# M55M1 register map
File version: 1.0
Registers are 32-bit, read-write, reset 0x0 unless marked. A register's access mark holds for its fields unless they carry their own. Offsets are from the block's base; [hi:lo] are bit positions; {n}, {i} and the like mark numbered series; 'fields as' and 'values as' point back to an identical list.

## I2C0 — I2C Register Map
Base 0x40248000
Same registers: I2C2 0x40249000, I2C1 0x40288000, I2C3 0x40289000, I2C0_NS 0x50248000, I2C2_NS 0x50249000, I2C1_NS 0x50288000, I2C3_NS 0x50289000
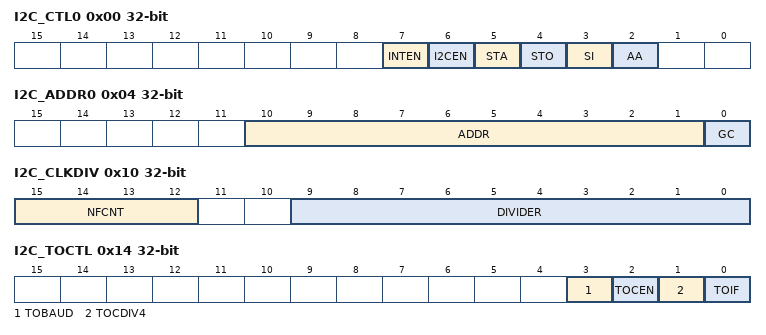
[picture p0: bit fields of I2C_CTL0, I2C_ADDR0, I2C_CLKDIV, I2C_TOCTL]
0x00 I2C_CTL0 — I2C Control Register 0
  [7] INTEN — Enable Interrupt
    0=I2C interrupt Disabled; 1=I2C interrupt Enabled
  [6] I2CEN — I2C Controller Enable Bit
    0=I2C controller Disabled; 1=I2C controller Enabled
  [5] STA — I2C START Control. Setting STA to logic 1 to enter Master mode, the I2C hardware sends a START or repeat START condition to bus when the bus is free. This bit will be cleared by hardware automatically.
  [4] STO — I2C STOP Control. In Master mode, setting STO to transmit a STOP condition to bus then I2C controller will check the bus condition if a STOP condition is detected. This bit will be cleared by hardware automatically.
  [3] SI — I2C Interrupt Flag. When a new I2C state is present in the I2C_STATUS0 register, the SI flag is set by hardware. If bit INTEN (I2C_CTL0 [7]) is set, the I2C interrupt is requested. SI must be cleared by software. Clear SI by writing 1 to this bit. For ACKMEN is set in slave read mode, the SI flag is set in 8th clock period for user to confirm the acknowledge bit and 9th clock period for user to read the data in the data buffer.
  [2] AA — Assert Acknowledge Control
0x04 I2C_ADDR0 — I2C Slave Address Register0
  [10:1] ADDR — I2C Address. The content of this register is irrelevant when I2C is in Master mode. In the slave mode, the seven most significant bits must be loaded with the chip's own address. The I2C hardware will react if either of the address is matched. Note: When software set 10'h000, the address cannot be used.
  [0] GC — General Call Function
    0=General Call Function Disabled; 1=General Call Function Enabled
0x08 I2C_DAT — I2C Data Register
  [7:0] DAT — I2C Data. Bit [7:0] is located with the 8-bit transferred/received data of I2C serial port.
0x0C I2C_STATUS0 ro reset 0xF8 — I2C Status Register 0
  [7:0] STATUS — I2C Status
0x10 I2C_CLKDIV — I2C Clock Divided Register
  [15:12] NFCNT — Noise Filter Count. The register bits control the input filter width. If the pulse width is narrower than the setting((3+N)*PCLK), it will be ignored. 0 : filter width 3*PCLK. 1 : filter width 4*PCLK. N : filter width (3+N)*PCKL. Note: Filter width Min :3*PCLK, Max : 18*PCLK
  [9:0] DIVIDER — I2C Clock Divided. Note: The minimum value of DIVIDER is 4.
0x14 I2C_TOCTL — I2C Time-out Control Register
  [3] TOBAUD — Time-out Counter Input Clock Using Baud Rate Frequency. When enabled, the time-out counter is using baud rate.
    0=Time-out counter is using PCLK or PCLK/4; 1=Time-out counter is using IC baud rate
  [2] TOCEN — Time-out Counter Enable Bit. When enabled, the 14-bit time-out counter will start counting when SI is cleared. Setting flag SI to '1' will reset counter and re-start up counting after SI is cleared.
    0=Time-out counter Disabled; 1=Time-out counter Enabled
  [1] TOCDIV4 — Time-out Counter Input Clock Divided by 4. When enabled, the time-out period is extended 4 times. Note: This bit only worked when I2C_TOCTL[3] is set to 0.
    0=Time-out period is extend 4 times Disabled; 1=Time-out period is extend 4 times Enabled
  [0] TOIF — Time-out Flag. This bit is set by hardware when I2C time-out happened and it can interrupt CPU if I2C interrupt enable bit (INTEN) is set to 1. Note: Software can write 1 to clear this bit.
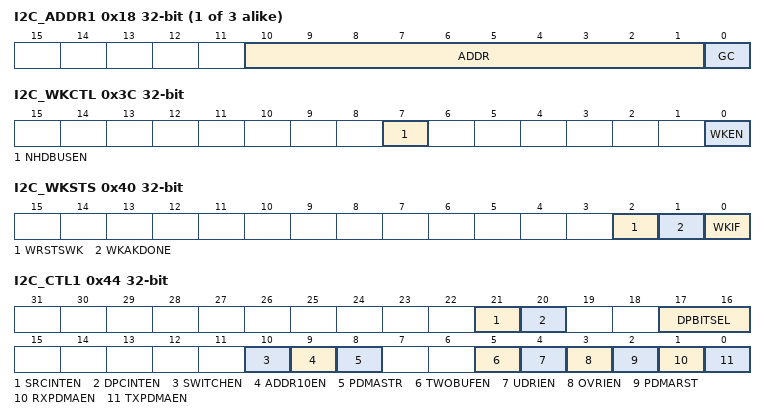
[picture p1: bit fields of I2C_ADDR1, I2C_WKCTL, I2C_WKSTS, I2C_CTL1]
{0x14+4i} I2C_ADDR{i} (i=1..3) — I2C Slave Address Register{i}
  fields as I2C_ADDR0
{0x24+4i} I2C_ADDRMSK{i} (i=0..3) — I2C Slave Address Mask Register{i}
  [10:1] ADDRMSK — I2C Address Mask. I2C bus controllers support multiple address recognition with four address mask register. When the bit in the address mask register is set to one, it means the received corresponding address bit is don't-care. If the bit is set to zero, that means the received corresponding register bit should be exact the same as address register. Note: The wake-up function cannot use address mask in 10-bit mode.
    0=Mask Disabled (the received corresponding register bit should be exact the same as address register.); 1=Mask Enabled (the received corresponding address bit is don't care.)
0x3C I2C_WKCTL — I2C Wake-up Control Register
  [7] NHDBUSEN — I2C No Hold BUS Enable Bit. Note: The I2C controller could respond when WKIF event is not clear, it may cause error data transmitted or received. If data transmitted or received when WKIF event is not clear, user must reset I2C controller and execute the original operation again.
    0=I2C hold bus after wake-up; 1=I2C don't hold bus after wake-up
  [0] WKEN — I2C Wake-up Enable Bit
    0=I2C wake-up function Disabled; 1=I2C wake-up function Enabled
0x40 I2C_WKSTS — I2C Wake-up Status Register
  [2] WRSTSWK — Read/Write Status Bit in Address Wakeup Frame. Note: This bit will be cleared when software can write 1 to WKAKDONE bit.
    0=Write command be record on the address match wakeup frame; 1=Read command be record on the address match wakeup frame
  [1] WKAKDONE — Wakeup Address Frame Acknowledge Bit Done. Note: This bit can't release WKIF. Software can write 1 to clear this bit.
    0=The ACK bit cycle of address match frame isn't done; 1=The ACK bit cycle of address match frame is done in power-down
  [0] WKIF — I2C Wake-up Flag. When chip is woken up from Power-down mode by I2C, this bit is set to 1. Software can write 1 to clear this bit.
0x44 I2C_CTL1 — I2C Control Register 1
  [21] SRCINTEN — Slave Read Command Interrupt Enable Bit
    0=Slave Read Command Interrupt Disabled; 1=Slave Read Command Interrupt Enabled
  [20] DPCINTEN — Data Phase Count Interrupt Enable Bit
    0=Data Phase Count Interrupt Disabled; 1=Data Phase Count Interrupt Enabled
  [17:16] DPBITSEL — Data Phase Bit Count Select
    0=DPCIF never set by hardware; 1=When I2C is transfer data and bit count equal to 6, DPCIF will be set by hardware; 2=When I2C is transfer data and bit count equal to 7, DPCIF will be set by hardware; 3=When I2C is transfer data and bit count equal to 8, DPCIF will be set by hardware
  [10] SWITCHEN — SCL And SDA Pin Switch Enable Bit. Note: Original pin configuration table is shown in Basic Configuration chapter.
    0=IC use original pin configuration; 1=IC switch SCL and SDA pin configuration
  [9] ADDR10EN — Address 10-bit Function Enable Bit
    0=Address match 10-bit function Disabled; 1=Address match 10-bit function Enabled
  [8] PDMASTR — PDMA Stretch Bit
    0=I2C send STOP automatically after PDMA transfer done. (only master TX); 1=I2C SCL bus is stretched by hardware after PDMA transfer done if the SI is not cleared. (only master TX)
  [5] TWOBUFEN — Two-level BUFFER Enable Bit. Set to enable the two-level buffer for I2C transmitted or received buffer. It is used to improve the performance of the I2C bus.
    0=Two-level buffer Disabled; 1=Two-level buffer Enabled
  [4] UDRIEN — I2C Under Run Interrupt Control Bit. Setting UDRIEN to logic 1 will send a interrupt to system when the TWOBUFEN bit is enabled and there is under run event happened in transmitted buffer.
  [3] OVRIEN — I2C over Run Interrupt Control Bit. Setting OVRIEN to logic 1 will send a interrupt to system when the TWOBUFEN bit is enabled and there is over run event in received buffer.
  [2] PDMARST — PDMA Reset
    0=No effect; 1=Reset the I2C request to PDMA
  [1] RXPDMAEN — PDMA Receive Channel Available
    0=Receive PDMA function Disabled; 1=Receive PDMA function Enabled
  [0] TXPDMAEN — PDMA Transmit Channel Available
    0=Transmit PDMA function Disabled; 1=Transmit PDMA function Enabled
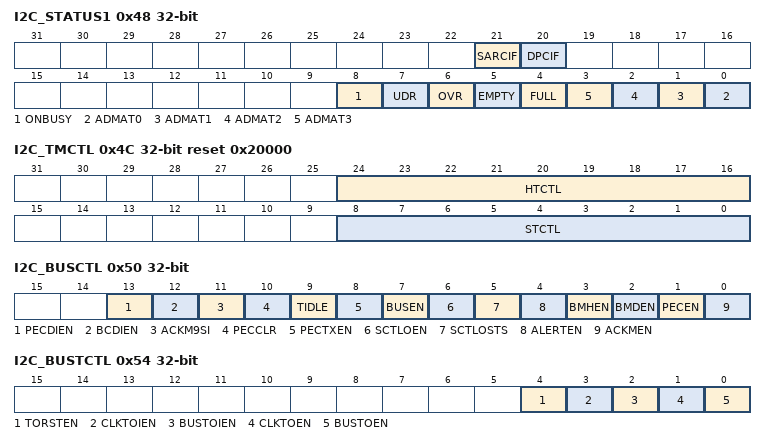
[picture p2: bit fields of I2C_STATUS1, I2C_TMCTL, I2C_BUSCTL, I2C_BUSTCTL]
0x48 I2C_STATUS1 — I2C Status Register 1
  [21] SARCIF — Slave Address Read Command Interrupt Flag. This bit is set by hardware when I2C receive address match read command. This bit is cleared by write 1 to it.
  [20] DPCIF — Data Phase Count Interrupt Flag. This bit is set by hardware when I2C transfer bit count equal to DPBITSEL setting. This bit is cleared by write 1 to it.
  [8] ONBUSY ro — On Bus Busy (Read Only). Indicates that a communication is in progress on the bus. It is set by hardware when a START condition is detected. It is cleared by hardware when a STOP condition is detected.
    0=The bus is IDLE (both SCL and SDA High); 1=The bus is busy
  [7] UDR — I2C Under Run Status Bit. Note: This bit is read only.
  [6] OVR — I2C over Run Status Bit. Note: This bit is read only.
  [5] EMPTY — TWO-LEVEL BUFFER EMPTY. This bit is set when POINTER is equal to 0. Note: This bit is read only.
  [4] FULL — TWO-LEVEL BUFFER FULL. This bit is set when POINTER is equal to 2. Note: This bit is read only.
  [n] ADMAT{n} (n=0..3) — I2C Address {n} Match Status. When address {n} is matched, hardware will inform which address used. This bit will set to 1, and software can write 1 to clear this bit.
0x4C I2C_TMCTL reset 0x20000 — I2C Timing Configure Control Register
  [24:16] HTCTL — Hold Time Configure Control. This field is used to generate the delay timing between SCL falling edge and SDA rising edge in transmission mode.
  [8:0] STCTL — Setup Time Configure Control. This field is used to generate a delay timing between SDA falling edge and SCL rising edge in transmission mode. Note: Setup time setting should not make SCL output less than three PCLKs.
0x50 I2C_BUSCTL — I2C Bus Management Control Register
  [13] PECDIEN — Packet Error Checking Byte Transfer Done Interrupt Enable Bit
    0=PEC transfer done interrupt Disabled; 1=PEC transfer done interrupt Enabled
  [12] BCDIEN — Packet Error Checking Byte Count Done Interrupt Enable Bit
    0=Byte count done interrupt Disabled; 1=Byte count done interrupt Enabled
  [11] ACKM9SI — Acknowledge Manual Enable Extra SI Interrupt
    0=There is no SI interrupt in the 9th clock cycle when the BUSEN =1 and ACKMEN =1; 1=There is SI interrupt in the 9th clock cycle when the BUSEN =1 and ACKMEN =1
  [10] PECCLR — PEC Clear at Repeat Start. The calculation of PEC starts when PECEN is set to 1 and it is cleared when the STA or STO bit is detected. This PECCLR bit is used to enable the condition of REPEAT START can clear the PEC calculation.
    0=PEC calculation is cleared by 'Repeat Start' function Disabled; 1=PEC calculation is cleared by 'Repeat Start' function Enabled
  [9] TIDLE — Timer Check in Idle State. The BUSTOUT is used to calculate the time-out of clock low in bus active and the idle period in bus Idle. This bit is used to define which condition is enabled. Note: The BUSY (I2C_BUSSTS[0]) indicate the current bus state.
    0=BUSTOUT is used to calculate the clock low period in bus active; 1=BUSTOUT is used to calculate the IDLE period in bus Idle
  [8] PECTXEN — Packet Error Checking Byte Transmission/Reception
    0=No PEC transfer; 1=PEC transmission is requested
  [7] BUSEN — BUS Enable Bit. Note: When the bit is enabled, the internal 14-bit counter is used to calculate the time out event of clock low condition.
    0=The system management function Disabled; 1=The system management function Enabled
  [6] SCTLOEN — Suspend or Control Pin Output Enable Bit
    0=The SUSCON pin in input; 1=The output enable is active on the SUSCON pin
  [5] SCTLOSTS — Suspend/Control Data Output Status
    0=The output of SUSCON pin is low; 1=The output of SUSCON pin is high
  [4] ALERTEN — Bus Management Alert Enable Bit
    0=Release the BM_ALERT pin high and Alert Response Header disabled: 0001100x followed by NACK if both of BMDEN and ACKMEN are enabled. BM_ALERT pin not supported; 1=Drive BM_ALERT pin low and Alert Response Address Header enables: 0001100x followed by ACK if both of BMDEN and ACKMEN are enabled. BM_ALERT pin supported
  [3] BMHEN — Bus Management Host Enable Bit
    0=Host function Disabled; 1=Host function Enabled
  [2] BMDEN — Bus Management Device Default Address Enable Bit
    0=Device default address Disable. When the address 0'b1100001x comes and either BMDEN or ACKMEN is disabled, the device responses NACK; 1=Device default address Enabled. When the address 0'b1100001x comes and both BMDEN and ACKMEN are enabled, the device responses ACK
  [1] PECEN — Packet Error Checking Calculation Enable Bit. Note: When I2C enter power-down mode, the bit should be enabled after wake-up if needed PEC calculation.
    0=Packet Error Checking Calculation Disabled; 1=Packet Error Checking Calculation Enabled
  [0] ACKMEN — Acknowledge Control by Manual. In order to allow ACK control in slave reception including the command and data, slave byte control mode must be enabled by setting the ACKMEN bit.
    0=Slave byte control Disabled; 1=Slave byte control Enabled. The 9th bit can response the ACK or NACK according the received data by user. When the byte is received, stretching the SCL signal low between the 8th and 9th SCL pulse
0x54 I2C_BUSTCTL — I2C Bus Management Timer Control Register
  [4] TORSTEN — Time Out Reset Enable Bit
    0=I2C state machine reset Disabled; 1=I2C state machine reset Enabled. (The clock and data bus will be released to high)
  [3] CLKTOIEN — Extended Clock Time Out Interrupt Enable Bit
    0=Clock time out interrupt Disabled; 1=Clock time out interrupt Enabled
  [2] BUSTOIEN — Time-out Interrupt Enable Bit
    0=SCL low time-out interrupt Disabled. Bus IDLE time-out interrupt Disabled; 1=SCL low time-out interrupt Enabled. Bus IDLE time-out interrupt Enabled
  [1] CLKTOEN — Cumulative Clock Low Time Out Enable Bit. For Master, it calculates the period from START to ACK. For Slave, it calculates the period from START to STOP
    0=Cumulative clock low time-out detection Disabled; 1=Cumulative clock low time-out detection Enabled
  [0] BUSTOEN — Bus Time Out Enable Bit
    0=Bus clock low time-out detection Disabled; 1=Bus clock low time-out detection Enabled (bus clock is low for more than BUSTO (I2C_BUSTOUT[7:0]) (in TIDLE=0) or high more than BUSTO (in TIDLE =1)
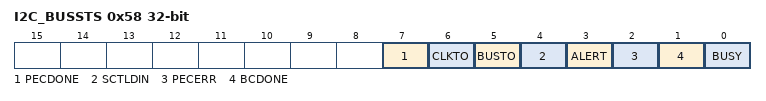
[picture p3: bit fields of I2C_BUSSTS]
0x58 I2C_BUSSTS — I2C Bus Management Status Register
  [7] PECDONE — PEC Byte Transmission/Receive Done. Note: Software can write 1 to clear this bit.
    0=PEC transmission/ receive is not finished when the PECEN is set; 1=PEC transmission/ receive is finished when the PECEN is set
  [6] CLKTO — Clock Low Cumulate Time-out Status. Note: Software can write 1 to clear this bit.
    0=Cumulative clock low is no any time-out; 1=Cumulative clock low time-out occurred
  [5] BUSTO — Bus Time-out Status. In bus busy, the bit indicates the total clock low time-out event occurred; otherwise, it indicates the bus idle time-out event occurred. Note: Software can write 1 to clear this bit.
    0=There is no any time-out or external clock time-out; 1=A time-out or external clock time-out occurred
  [4] SCTLDIN ro — Bus Suspend or Control Signal Input Status (Read Only). Note: This bit is read only.
    0=The input status of SUSCON pin is 0; 1=The input status of SUSCON pin is 1
  [3] ALERT — SMBus Alert Status. Note: 1. The SMBALERT pin is an open-drain pin, the pull-high resistor is must in the system. 2. Software can write 1 to clear this bit.
    0=SMBALERT pin state is low. No SMBALERT event; 1=SMBALERT pin state is high. There is SMBALERT event (falling edge) is detected in SMALERT pin when the BMHEN = 1 (SMBus host configuration) and the ALERTEN = 1
  [2] PECERR — PEC Error in Reception. Note: Software can write 1 to clear this bit.
    0=PEC value equal the received PEC data packet; 1=PEC value doesn't match the receive PEC data packet
  [1] BCDONE — Byte Count Transmission/Receive Done. Note: Software can write 1 to clear this bit.
    0=Byte count transmission/ receive is not finished when the PECEN is set; 1=Byte count transmission/ receive is finished when the PECEN is set
  [0] BUSY ro — Bus Busy (Read Only). Indicates that a communication is in progress on the bus. It is set by hardware when a START condition is detected. It is cleared by hardware when a STOP condition is detected. Note: This bit is read only.
    0=Bus is IDLE (both SCL and SDA High); 1=Bus is busy
0x5C I2C_PKTSIZE — I2C Packet Error Checking Byte Number Register
  [8:0] PLDSIZE — Transfer Byte Number. The transmission or receive byte number in one transaction when the PECEN is set. The maximum transaction or receive byte is 256 Bytes. Note: The byte number counting includes address, command code, and data frame.
0x60 I2C_PKTCRC ro — I2C Packet Error Checking Byte Value Register
  [7:0] PECCRC — Packet Error Checking Byte Value
0x64 I2C_BUSTOUT reset 0x5 — I2C Bus Management Timer Register
  [7:0] BUSTO — Bus Management Time-out Value. Indicates the bus time-out value in bus is IDLE or SCL low. Note: If the user wants to revise the value of BUSTOUT, the TORSTEN (I2C_BUSTCTL[4]) bit shall be set to 1 and cleared to 0 first when the BUSEN(I2C_BUSCTL[7]) is set.
0x68 I2C_CLKTOUT reset 0x5 — I2C Bus Management Clock Low Timer Register
  [7:0] CLKTO — Bus Clock Low Timer. The field is used to configure the cumulative clock extension time-out. Note: If the user wants to revise the value of CLKTOUT, the TORSTEN bit shall be set to 1 and cleared to 0 first when the BUSEN is set.
